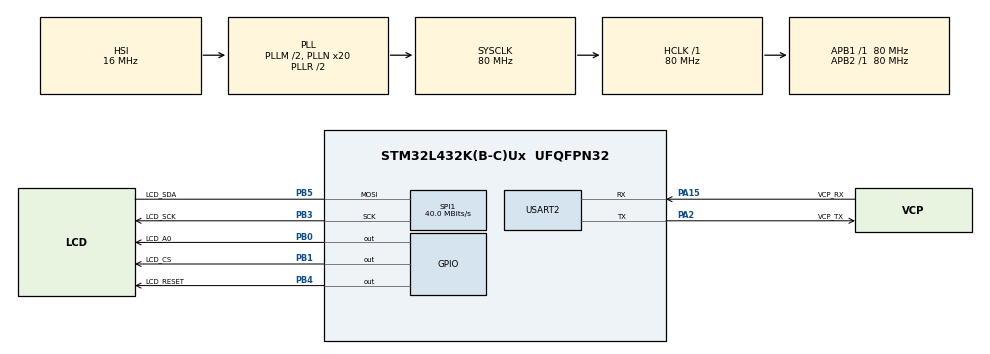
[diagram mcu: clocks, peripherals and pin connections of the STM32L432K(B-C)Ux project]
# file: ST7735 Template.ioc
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Mcu.Family=STM32L4
Mcu.Name=STM32L432K(B-C)Ux
Mcu.Package=UFQFPN32
NVIC.PriorityGroup=NVIC_PRIORITYGROUP_4
PA0.GPIO_Label=MCO [High speed clock in]
PA0.Signal=RCC_CK_IN
PA13\ (JTMS-SWDIO).GPIO_Label=SWDIO
PA13\ (JTMS-SWDIO).Signal=SYS_JTMS-SWDIO
PA14\ (JTCK-SWCLK).GPIO_Label=SWCLK
PA14\ (JTCK-SWCLK).Signal=SYS_JTCK-SWCLK
PA15\ (JTDI).GPIO_Label=VCP_RX
PA15\ (JTDI).Mode=Asynchronous
PA15\ (JTDI).Signal=USART2_RX
PA2.GPIO_Label=VCP_TX
PA2.Mode=Asynchronous
PA2.Signal=USART2_TX
PB0.GPIO_Label=LCD_A0
PB0.GPIO_Speed=GPIO_SPEED_FREQ_VERY_HIGH
PB0.PinState=GPIO_PIN_RESET
PB0.Signal=GPIO_Output
PB1.GPIO_Label=LCD_CS
PB1.GPIO_Speed=GPIO_SPEED_FREQ_VERY_HIGH
PB1.Signal=GPIO_Output
PB3\ (JTDO-TRACESWO).GPIO_Label=LCD_SCK
PB3\ (JTDO-TRACESWO).Mode=Simplex_Bidirectional_Master
PB3\ (JTDO-TRACESWO).Signal=SPI1_SCK
PB4\ (NJTRST).GPIO_Label=LCD_RESET
PB4\ (NJTRST).GPIO_Speed=GPIO_SPEED_FREQ_VERY_HIGH
PB4\ (NJTRST).Signal=GPIO_Output
PB5.GPIO_Label=LCD_SDA
PB5.Mode=Simplex_Bidirectional_Master
PB5.Signal=SPI1_MOSI
PC14-OSC32_IN\ (PC14).Signal=RCC_OSC32_IN
PC15-OSC32_OUT\ (PC15).Signal=RCC_OSC32_OUT
ProjectManager.HeapSize=0x200
ProjectManager.StackSize=0x400
ProjectManager.TargetToolchain=TrueSTUDIO
RCC.ADCFreq_Value=32000000
RCC.AHBFreq_Value=80000000
RCC.APB1Freq_Value=80000000
RCC.APB1TimFreq_Value=80000000
RCC.APB2Freq_Value=80000000
RCC.APB2TimFreq_Value=80000000
RCC.CortexFreq_Value=80000000
RCC.HCLKFreq_Value=80000000
RCC.HSE_VALUE=8000000
RCC.HSI16_VALUE=16000000
RCC.HSI48_VALUE=48000000
RCC.HSI_VALUE=16000000
RCC.LSE_VALUE=32768
RCC.MSI_VALUE=4000000
RCC.PLLM=2
RCC.PLLMUL=RCC_PLLMUL_4
RCC.PLLN=20
RCC.PLLSourceVirtual=RCC_PLLSOURCE_HSI
RCC.SYSCLKFreq_VALUE=80000000
RCC.SYSCLKSource=RCC_SYSCLKSOURCE_PLLCLK
RCC.USBFreq_Value=32000000
RCC.VCOOutputFreq_Value=160000000
SPI1.BaudRatePrescaler=SPI_BAUDRATEPRESCALER_2
SPI1.CalculateBaudRate=40.0 MBits/s
SPI1.DataSize=SPI_DATASIZE_8BIT
SPI1.Direction=SPI_DIRECTION_1LINE
SPI1.Mode=SPI_MODE_MASTER
SPI1.VirtualType=VM_MASTER
USART2.VirtualMode-Asynchronous=VM_ASYNC
USART2.WordLength=WORDLENGTH_8B
board=NUCLEO-L432KC

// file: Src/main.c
/*******************************************************************************
  * File Name          : main.c
  * Description        :
  *   Hello world Graphics LCD way! This code uses the ST7735 library written by
  *   Oleg Yakovlev (https://github.com/OlegUA/ST7735) with some small modifica-
  *   tions in order to make it work with STM32L432KC and newer HAL functions
  *   UART2 is also enabled and can be used to communicate with the host compu-
  *   ter using ST-LINK's builtin VCP.
  *   Target board: STM NUCLEO32 (STM32L432KC based)
  *   Pins used:
  *   - PA2 		- UART2 TX (connected do the VCP)
  *   - PA15		- UART2 RX (connected to the VCP)
  *   - PB0 (D3)	- LCD_A0
  *   - PB1 (D6)	- LCD_CS
  *   - PB3 (D13)	- LCD_SCK (SPI1 clock)
  *   - PB4 (D12)	- LCD_RESET
  *   - PB5 (D11)	- LCD_SDA (SPI1 MOSI)
  *
  * http://sctec.com.br/blog/st7735-spi-lcd-with-the-stm32l432-microcontroller/
  *
  * Author:              FАbio Pereira
  * Date:                06/12/2017
  ******************************************************************************
  */
#include "ST7735_hw_config.h"
#include "main.h"
#include "stm32l4xx_hal.h"

/* USER CODE BEGIN Includes */
#include "ST7735.h"
/* USER CODE END Includes */

SPI_HandleTypeDef hspi1;

UART_HandleTypeDef huart2;

/* USER CODE BEGIN PV */
/* Private variables ---------------------------------------------------------*/

/* USER CODE END PV */

void SystemClock_Config(void);
static void MX_GPIO_Init(void);
static void MX_USART2_UART_Init(void);
static void MX_SPI1_Init(void);

/* USER CODE BEGIN PFP */
/* Private function prototypes -----------------------------------------------*/

/* USER CODE END PFP */

int main(void)
{

  /* MCU Configuration----------------------------------------------------------*/

  /* Reset of all peripherals, Initializes the Flash interface and the Systick. */
  HAL_Init();

  /* Configure the system clock */
  SystemClock_Config();

  /* Initialize all configured peripherals */
  MX_GPIO_Init();
  MX_USART2_UART_Init();
  MX_SPI1_Init();

  /* USER CODE BEGIN 2 */
  lcd7735_initR(INITR_REDTAB);
  lcd7735_setFont((uint8_t *)&SmallFont[0]);
  lcd7735_fillScreen(ST7735_BLACK);
  lcd7735_fillRect(4,58,119,35,ST7735_GREEN);
  lcd7735_setForeground(ST7735_WHITE);
  lcd7735_setTransparent(1);
  lcd7735_print("Hello World!",15,62,0);
  lcd7735_print("GLCD way!",25,75,0);
  lcd7735_setTransparent(0);
  /* USER CODE END 2 */

  /* Infinite loop */
  while (1)
  {

  }

}

/** System Clock Configuration
*/
void SystemClock_Config(void)
{

  RCC_OscInitTypeDef RCC_OscInitStruct;
  RCC_ClkInitTypeDef RCC_ClkInitStruct;
  RCC_PeriphCLKInitTypeDef PeriphClkInit;

    /**Initializes the CPU, AHB and APB busses clocks
    */
  RCC_OscInitStruct.OscillatorType = RCC_OSCILLATORTYPE_HSI;
  RCC_OscInitStruct.HSIState = RCC_HSI_ON;
  RCC_OscInitStruct.HSICalibrationValue = 16;
  RCC_OscInitStruct.PLL.PLLState = RCC_PLL_ON;
  RCC_OscInitStruct.PLL.PLLSource = RCC_PLLSOURCE_HSI;
  RCC_OscInitStruct.PLL.PLLM = 2;
  RCC_OscInitStruct.PLL.PLLN = 20;
  RCC_OscInitStruct.PLL.PLLP = RCC_PLLP_DIV7;
  RCC_OscInitStruct.PLL.PLLQ = RCC_PLLQ_DIV2;
  RCC_OscInitStruct.PLL.PLLR = RCC_PLLR_DIV2;
  if (HAL_RCC_OscConfig(&RCC_OscInitStruct) != HAL_OK)
  {
    _Error_Handler(__FILE__, __LINE__);
  }

    /**Initializes the CPU, AHB and APB busses clocks
    */
  RCC_ClkInitStruct.ClockType = RCC_CLOCKTYPE_HCLK|RCC_CLOCKTYPE_SYSCLK
                              |RCC_CLOCKTYPE_PCLK1|RCC_CLOCKTYPE_PCLK2;
  RCC_ClkInitStruct.SYSCLKSource = RCC_SYSCLKSOURCE_PLLCLK;
  RCC_ClkInitStruct.AHBCLKDivider = RCC_SYSCLK_DIV1;
  RCC_ClkInitStruct.APB1CLKDivider = RCC_HCLK_DIV1;
  RCC_ClkInitStruct.APB2CLKDivider = RCC_HCLK_DIV1;

  if (HAL_RCC_ClockConfig(&RCC_ClkInitStruct, FLASH_LATENCY_4) != HAL_OK)
  {
    _Error_Handler(__FILE__, __LINE__);
  }

  PeriphClkInit.PeriphClockSelection = RCC_PERIPHCLK_USART2;
  PeriphClkInit.Usart2ClockSelection = RCC_USART2CLKSOURCE_PCLK1;
  if (HAL_RCCEx_PeriphCLKConfig(&PeriphClkInit) != HAL_OK)
  {
    _Error_Handler(__FILE__, __LINE__);
  }

    /**Configure the main internal regulator output voltage
    */
  if (HAL_PWREx_ControlVoltageScaling(PWR_REGULATOR_VOLTAGE_SCALE1) != HAL_OK)
  {
    _Error_Handler(__FILE__, __LINE__);
  }

    /**Configure the Systick interrupt time
    */
  HAL_SYSTICK_Config(HAL_RCC_GetHCLKFreq()/1000);

    /**Configure the Systick
    */
  HAL_SYSTICK_CLKSourceConfig(SYSTICK_CLKSOURCE_HCLK);

  /* SysTick_IRQn interrupt configuration */
  HAL_NVIC_SetPriority(SysTick_IRQn, 0, 0);
}

/* SPI1 init function */
static void MX_SPI1_Init(void)
{

  hspi1.Instance = SPI1;
  hspi1.Init.Mode = SPI_MODE_MASTER;
  hspi1.Init.Direction = SPI_DIRECTION_1LINE;
  hspi1.Init.DataSize = SPI_DATASIZE_8BIT;
  hspi1.Init.CLKPolarity = SPI_POLARITY_LOW;
  hspi1.Init.CLKPhase = SPI_PHASE_1EDGE;
  hspi1.Init.NSS = SPI_NSS_SOFT;
  hspi1.Init.BaudRatePrescaler = SPI_BAUDRATEPRESCALER_2;
  hspi1.Init.FirstBit = SPI_FIRSTBIT_MSB;
  hspi1.Init.TIMode = SPI_TIMODE_DISABLE;
  hspi1.Init.CRCCalculation = SPI_CRCCALCULATION_DISABLE;
  hspi1.Init.CRCPolynomial = 7;
  hspi1.Init.CRCLength = SPI_CRC_LENGTH_DATASIZE;
  hspi1.Init.NSSPMode = SPI_NSS_PULSE_ENABLE;
  if (HAL_SPI_Init(&hspi1) != HAL_OK)
  {
    _Error_Handler(__FILE__, __LINE__);
  }

}

/* USART2 init function */
static void MX_USART2_UART_Init(void)
{

  huart2.Instance = USART2;
  huart2.Init.BaudRate = 115200;
  huart2.Init.WordLength = UART_WORDLENGTH_8B;
  huart2.Init.StopBits = UART_STOPBITS_1;
  huart2.Init.Parity = UART_PARITY_NONE;
  huart2.Init.Mode = UART_MODE_TX_RX;
  huart2.Init.HwFlowCtl = UART_HWCONTROL_NONE;
  huart2.Init.OverSampling = UART_OVERSAMPLING_16;
  huart2.Init.OneBitSampling = UART_ONE_BIT_SAMPLE_DISABLE;
  huart2.AdvancedInit.AdvFeatureInit = UART_ADVFEATURE_NO_INIT;
  if (HAL_UART_Init(&huart2) != HAL_OK)
  {
    _Error_Handler(__FILE__, __LINE__);
  }

}

/** Configure pins as
        * Analog
        * Input
        * Output
        * EVENT_OUT
        * EXTI
*/
static void MX_GPIO_Init(void)
{

  GPIO_InitTypeDef GPIO_InitStruct;

  /* GPIO Ports Clock Enable */
  __HAL_RCC_GPIOC_CLK_ENABLE();
  __HAL_RCC_GPIOA_CLK_ENABLE();
  __HAL_RCC_GPIOB_CLK_ENABLE();

  /*Configure GPIO pin Output Level */
  HAL_GPIO_WritePin(GPIOB, LCD_A0_Pin|LCD_CS_Pin|LCD_RESET_Pin, GPIO_PIN_RESET);

  /*Configure GPIO pins : LCD_A0_Pin LCD_CS_Pin LCD_RESET_Pin */
  GPIO_InitStruct.Pin = LCD_A0_Pin|LCD_CS_Pin|LCD_RESET_Pin;
  GPIO_InitStruct.Mode = GPIO_MODE_OUTPUT_PP;
  GPIO_InitStruct.Pull = GPIO_NOPULL;
  GPIO_InitStruct.Speed = GPIO_SPEED_FREQ_VERY_HIGH;
  HAL_GPIO_Init(GPIOB, &GPIO_InitStruct);

}

void _Error_Handler(char * file, int line)
{
  while(1)
  {
  }
}

/************************ (C) COPYRIGHT STMicroelectronics *****END OF FILE****/
